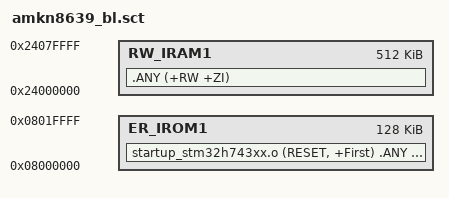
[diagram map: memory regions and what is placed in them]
; AMKN8639 OpenBLT scatter (V3)
LR_IROM1 0x08000000 0x00020000 {
  ER_IROM1 0x08000000 0x00020000 {
   startup_stm32h743xx.o (RESET, +First)   .ANY (+RO)
  }
  RW_IRAM1 0x24000000 0x00080000 {
   .ANY (+RW +ZI)
  }
}
